# RA register map
Vendor: Renesas; Series: All Chips; File version: x.xx
Registers are 32-bit, read-write, reset 0x0 unless marked. A register's access mark holds for its fields unless they carry their own. Offsets are from the block's base; [hi:lo] are bit positions; lines under a group give offsets from that group; {n}, {i} and the like mark numbered series.

## R_KINT — Key Interrupt Function
Base 0x40080000
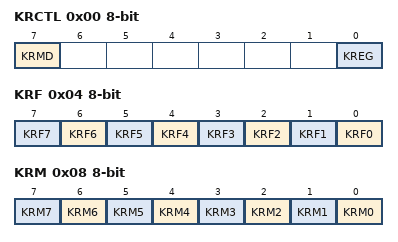
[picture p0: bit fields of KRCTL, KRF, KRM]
0x00 KRCTL 8-bit — KEY Return Control Register
  [7] KRMD — Usage of Key Interrupt Flags(KR0 to KR7)
    0=Do not use key interrupt flags; 1=Use key interrupt flags
  [0] KREG — Detection Edge Selection (KRF0 to KRF7)
    0=Falling edge; 1=Rising edge
0x04 KRF 8-bit write-0-clears read-modifies — KEY Return Flag Register
  [all] fields
    0=No interrupt detected; 1=Interrupt detected
  [n] KRF{n} write-0-clears read-modifies (n=0..7) — Key interrupt flag {n}
0x08 KRM 8-bit — KEY Return Mode Register
  [all] fields
    0=Does not detect key interrupt signal; 1=Detect key interrupt signal
  [n] KRM{n} (n=0..7) — Key interrupt mode control {n}

## R_MMF — Memory Mirror Function
Base 0x40001000
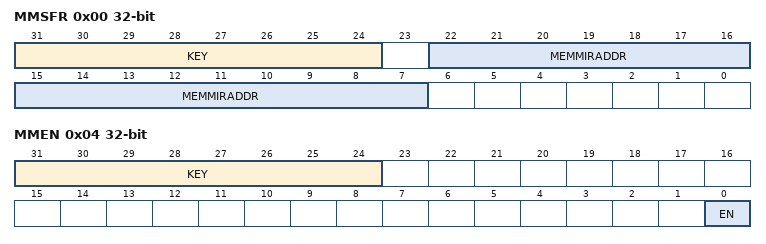
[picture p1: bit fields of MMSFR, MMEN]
0x00 MMSFR — MemMirror Special Function Register
  [31:24] KEY wo — MMSFR Key Code
    219=Writing to the MEMMIRADDR bits are valid, when the KEY bits are written 0xDB; other=others (Writing to the MEMMIRADDR bits are invalid.)
  [22:7] MEMMIRADDR — Specifies the memory mirror address.NOTE: A value cannot be set in the low-order 7 bits. These bits are fixed to 0.
0x04 MMEN — MemMirror Enable Register
  [31:24] KEY wo — MMEN Key Code
    219=Writing to the EN bit is valid, when the KEY bits are written 0xDB; other=others (Writing to the EN bit is invalid.)
  [0] EN — Memory Mirror Function Enable
    1=Memory Mirror Function is enabled; 0=Memory Mirror Function is disabled

## R_MPU_MMPU — Bus Master MPU
Base 0x40000000
{0x0+0x400*i} MMPU[{i}] (i=0..2) group — Bus Master MPU Registers
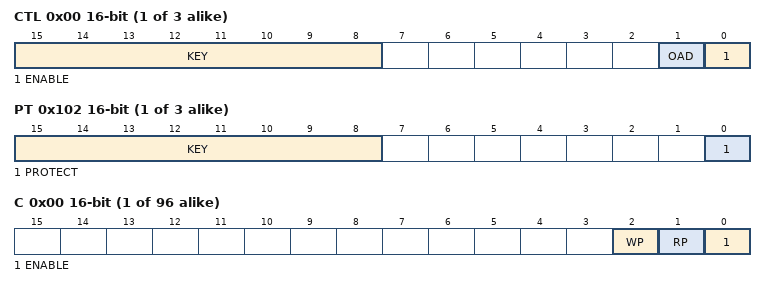
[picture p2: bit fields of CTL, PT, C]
  0x00 CTL 16-bit — Bus Master MPU Control Register
    [15:8] KEY wo — Write Keyword The data written to these bits are not stored.
      165=Writing to the OAD and ENABLE bit is valid, when the KEY bits are written 0xA5; other=others (Writing to the OAD and ENABLE bit is invalid.)
    [1] OAD — Operation after detection
      0=Non-maskable interrupt; 1=Internal reset
    [0] ENABLE — Master Group enable
      0=Master Group is disabled. Permission of all regions.; 1=Master Group is enabled. Protection of all regions.
  0x102 PT 16-bit — Protection of Register
    [15:8] KEY wo — Write Keyword The data written to these bits are not stored.
      165=Writing to the PROTECT bit is valid, when the KEY bits are written 0xA5; other=others (Writing to the PROTECT bit is invalid.)
    [0] PROTECT — Protection of region register
      0=All Bus Master MPU register writing is possible; 1=All Bus Master MPU register writing is protected. Read is possible.
  {0x200+0x10*j} REGION[{j}] (j=0..31) group — Address Region registers
    0x00 C 16-bit — Access Control Register
      [2] WP — Write protection
        0=Write permission; 1=Write protection
      [1] RP — Read protection
        0=Read permission; 1=Read protection
      [0] ENABLE — Region enable
        0=Group m Region n unit is disabled; 1=Group m Region n unit is enabled
    0x04 S — Start Address Register
      [31:0] MMPUSmn — Address where the region starts, for use in region determination.NOTE: The low-order 2 bits are fixed to 0.
    0x08 E reset 0x3 — End Address Register
      [31:0] MMPUEmn — Region end address registerAddress where the region end, for use in region determination.NOTE: The low-order 2 bits are fixed to 1.

## R_MPU_SMPU — Bus Slave MPU
Base 0x40000C00
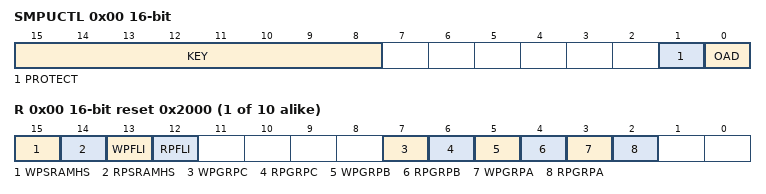
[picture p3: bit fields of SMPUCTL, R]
0x00 SMPUCTL 16-bit — Slave MPU Control Register
  [15:8] KEY wo — Key Code This bit is used to enable or disable rewriting of the PROTECT and OAD bit.
    165=Writing to the PROTECT and OAD bit is valid, when the KEY bits are written 0xA5; other=others (Writing to the PROTECT and OAD bit is invalid.)
  [1] PROTECT — Protection of register
    0=All Bus Slave register writing is possible; 1=All Bus Slave register writing is protected. Read is possible.
  [0] OAD — Master Group enable
    0=Non-maskable interrupt; 1=Internal reset
{0x10+4i} SMPU[{i}] (i=0..9) group — Access Control Structure for MBIU
  0x00 R 16-bit reset 0x2000 — Access Control Register for MBIU
    [15] WPSRAMHS — SRAMHS Write Protection
      0=Memory protection for SRAMHS writes from master group A, B, and C disabled; 1=Memory protection for SRAMHS writes from master group A, B, and C enabled
    [14] RPSRAMHS — SRAMHS Read Protection
      0=Memory protection for SRAMHS reads from master group A, B, and C disabled; 1=Memory protection for SRAMHS reads from master group A, B, and C enabled
    [13] WPFLI — Code Flash Memory Write Protection (Note: This bit is read as 1. The write value should be 1.)
      0=Setting prohibited; 1=Memory protection for code flash memory writes from master group A, B, and C enabled
    [12] RPFLI — Code Flash Memory Read Protection
      0=Memory protection for code flash memory reads from master group A, B, and C disabled; 1=Memory protection for code flash memory reads from master group A, B, and C enabled
    [7] WPGRPC — Master Group C Write protection
      0=Memory protection for master group C writes disabled; 1=Memory protection for master group C writes enabled
    [6] RPGRPC — Master Group C Read protection
      0=Memory protection for master group C reads disabled; 1=Memory protection for master group C reads enabled
    [5] WPGRPB — Master Group B Write protection
      0=Memory protection for master group B writes disabled; 1=Memory protection for master group B writes enabled
    [4] RPGRPB — Master Group B Read protection
      0=Memory protection for master group B reads disabled; 1=Memory protection for master group B reads enabled
    [3] WPGRPA — Master Group A Write protection
      0=Memory protection for master group A writes disabled; 1=Memory protection for master group A writes enabled
    [2] RPGRPA — Master Group A Read protection
      0=Memory protection for master group A reads disabled; 1=Memory protection for master group A reads enabled
